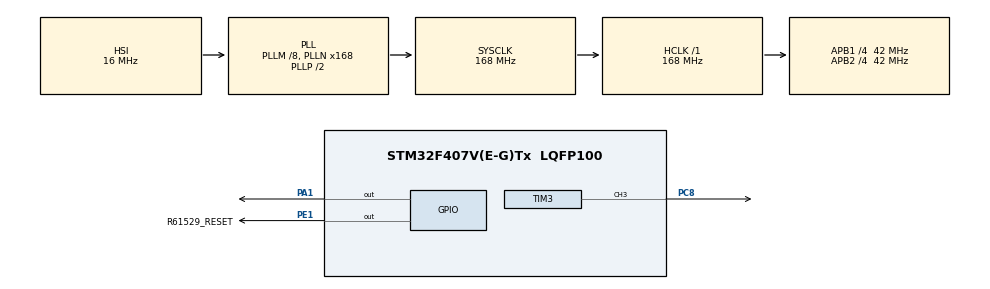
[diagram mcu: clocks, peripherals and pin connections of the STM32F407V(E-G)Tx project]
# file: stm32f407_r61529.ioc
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Mcu.Family=STM32F4
Mcu.Name=STM32F407V(E-G)Tx
Mcu.Package=LQFP100
NVIC.PriorityGroup=NVIC_PRIORITYGROUP_4
PA1.Signal=GPIO_Output
PC8.Signal=S_TIM3_CH3
PE1.GPIO_Label=R61529_RESET
PE1.Signal=GPIO_Output
ProjectManager.HeapSize=0x200
ProjectManager.StackSize=0x400
ProjectManager.TargetToolchain=STM32CubeIDE
RCC.48MHZClocksFreq_Value=84000000
RCC.AHBFreq_Value=168000000
RCC.APB1CLKDivider=RCC_HCLK_DIV4
RCC.APB1Freq_Value=42000000
RCC.APB1TimFreq_Value=84000000
RCC.APB2CLKDivider=RCC_HCLK_DIV4
RCC.APB2Freq_Value=42000000
RCC.APB2TimFreq_Value=84000000
RCC.CortexFreq_Value=168000000
RCC.HCLKFreq_Value=168000000
RCC.HSE_VALUE=25000000
RCC.HSI_VALUE=16000000
RCC.LSE_VALUE=32768
RCC.PLLM=8
RCC.PLLN=168
RCC.SYSCLKFreq_VALUE=168000000
RCC.SYSCLKSource=RCC_SYSCLKSOURCE_PLLCLK
RCC.VCOOutputFreq_Value=336000000
SH.S_TIM3_CH3.0=TIM3_CH3,PWM Generation3 CH3
TIM3.Channel-PWM\ Generation3\ CH3=TIM_CHANNEL_3
TIM3.Period=14000 - 1
TIM3.Prescaler=50
TIM3.Pulse-PWM\ Generation3\ CH3=7000 - 1
board=custom

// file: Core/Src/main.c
/* USER CODE BEGIN Header */
/**
  ******************************************************************************
  * @file           : main.c
  * @brief          : Main program body
  ******************************************************************************
  * @attention
  *
  * Copyright (c) 2023 STMicroelectronics.
  * All rights reserved.
  *
  * This software is licensed under terms that can be found in the LICENSE file
  * in the root directory of this software component.
  * If no LICENSE file comes with this software, it is provided AS-IS.
  *
  ******************************************************************************
  */
/* USER CODE END Header */
#include "main.h"

/* USER CODE BEGIN Includes */
#include "systick_timer.h"
#include "r61529.h"
#include "fonts.h"

/* USER CODE END Includes */

TIM_HandleTypeDef htim3;

void SystemClock_Config(void);
static void MX_GPIO_Init(void);
static void MX_TIM3_Init(void);
/* USER CODE BEGIN PFP */
void MCU_Init();
void Blink_LED();

/* USER CODE END PFP */

/* USER CODE BEGIN 0 */
void MCU_Init(){
	GPIO_InitTypeDef GPIO_InitStruct ={0};
	/** FMC GPIO Configuration
	PE7   ------> FMC_D4
	PE8   ------> FMC_D5
	PE9   ------> FMC_D6
	PE10   ------> FMC_D7
	PE11   ------> FMC_D8
	PE12   ------> FMC_D9
	PE13   ------> FMC_D10
	PE14   ------> FMC_D11
	PE15   ------> FMC_D12
	PD8   ------> FMC_D13
	PD9   ------> FMC_D14
	PD10   ------> FMC_D15
	PD11   ------> FMC_A16
	PD14   ------> FMC_D0
	PD15   ------> FMC_D1
	PC7   ------> FMC_NE1
	PD0   ------> FMC_D2
	PD1   ------> FMC_D3
	PD4   ------> FMC_NOE
	PD5   ------> FMC_NWE
	*/
	GPIO_InitStruct.Pin = GPIO_PIN_7|GPIO_PIN_8|GPIO_PIN_9|GPIO_PIN_10|GPIO_PIN_11
							|GPIO_PIN_12|GPIO_PIN_13|GPIO_PIN_14|GPIO_PIN_15;
	GPIO_InitStruct.Mode = GPIO_MODE_OUTPUT_PP;
	GPIO_InitStruct.Pull = GPIO_NOPULL;
	GPIO_InitStruct.Speed = GPIO_SPEED_FREQ_VERY_HIGH;
	HAL_GPIO_Init(GPIOE, &GPIO_InitStruct);

	GPIO_InitStruct.Pin = GPIO_PIN_8|GPIO_PIN_9|GPIO_PIN_10|GPIO_PIN_11|GPIO_PIN_14
							|GPIO_PIN_15|GPIO_PIN_0|GPIO_PIN_1|GPIO_PIN_4|GPIO_PIN_5;
	GPIO_InitStruct.Mode = GPIO_MODE_OUTPUT_PP;
	GPIO_InitStruct.Pull = GPIO_NOPULL;
	GPIO_InitStruct.Speed = GPIO_SPEED_FREQ_VERY_HIGH;
	HAL_GPIO_Init(GPIOD, &GPIO_InitStruct);

	GPIO_InitStruct.Pin = GPIO_PIN_7;
	GPIO_InitStruct.Mode = GPIO_MODE_OUTPUT_PP;
	GPIO_InitStruct.Pull = GPIO_NOPULL;
	GPIO_InitStruct.Speed = GPIO_SPEED_FREQ_VERY_HIGH;
	HAL_GPIO_Init(GPIOC, &GPIO_InitStruct);

	/*--------------------------------------------------------------------------*/
	/*--------------------------------------------------------------------------*/
	/*--------------------------------------------------------------------------*/
	HAL_NVIC_SetPriority(SysTick_IRQn, 0x0, 0x0);
	HAL_NVIC_EnableIRQ(SysTick_IRQn);

	HAL_TIM_PWM_Start(&htim3, TIM_CHANNEL_3);
	Init_Disp();
	ili9481_FillScreen(WHITE);
	r61529_WriteString(50, 50, "Mamka mu na toja ekran...", Font_11x18, BLACK, WHITE);
}

void Blink_LED(){
	static uint8_t state = 0;

	if(wait_ms_ch(0, 750)){
		if(state == 0){
			HAL_GPIO_WritePin(GPIOA, GPIO_PIN_1, GPIO_PIN_SET);
			state = 1;
		}else{
			HAL_GPIO_WritePin(GPIOA, GPIO_PIN_1, GPIO_PIN_RESET);
			state = 0;
		}
	}
}

/* USER CODE END 0 */

int main(void)
{

  /* MCU Configuration--------------------------------------------------------*/

  /* Reset of all peripherals, Initializes the Flash interface and the Systick. */
  HAL_Init();

  /* Configure the system clock */
  SystemClock_Config();

  /* Initialize all configured peripherals */
  MX_GPIO_Init();
  MX_TIM3_Init();
  /* USER CODE BEGIN 2 */
  MCU_Init();

  /* USER CODE END 2 */

  /* Infinite loop */
  /* USER CODE BEGIN WHILE */
  while(1){
	  Blink_LED();
    /* USER CODE END WHILE */
  }
}

void SystemClock_Config(void)
{
  RCC_OscInitTypeDef RCC_OscInitStruct = {0};
  RCC_ClkInitTypeDef RCC_ClkInitStruct = {0};

  /** Configure the main internal regulator output voltage
  */
  __HAL_RCC_PWR_CLK_ENABLE();
  __HAL_PWR_VOLTAGESCALING_CONFIG(PWR_REGULATOR_VOLTAGE_SCALE1);

  /** Initializes the RCC Oscillators according to the specified parameters
  * in the RCC_OscInitTypeDef structure.
  */
  RCC_OscInitStruct.OscillatorType = RCC_OSCILLATORTYPE_HSI;
  RCC_OscInitStruct.HSIState = RCC_HSI_ON;
  RCC_OscInitStruct.HSICalibrationValue = RCC_HSICALIBRATION_DEFAULT;
  RCC_OscInitStruct.PLL.PLLState = RCC_PLL_ON;
  RCC_OscInitStruct.PLL.PLLSource = RCC_PLLSOURCE_HSI;
  RCC_OscInitStruct.PLL.PLLM = 8;
  RCC_OscInitStruct.PLL.PLLN = 168;
  RCC_OscInitStruct.PLL.PLLP = RCC_PLLP_DIV2;
  RCC_OscInitStruct.PLL.PLLQ = 4;
  if (HAL_RCC_OscConfig(&RCC_OscInitStruct) != HAL_OK)
  {
    Error_Handler();
  }

  /** Initializes the CPU, AHB and APB buses clocks
  */
  RCC_ClkInitStruct.ClockType = RCC_CLOCKTYPE_HCLK|RCC_CLOCKTYPE_SYSCLK
                              |RCC_CLOCKTYPE_PCLK1|RCC_CLOCKTYPE_PCLK2;
  RCC_ClkInitStruct.SYSCLKSource = RCC_SYSCLKSOURCE_PLLCLK;
  RCC_ClkInitStruct.AHBCLKDivider = RCC_SYSCLK_DIV1;
  RCC_ClkInitStruct.APB1CLKDivider = RCC_HCLK_DIV4;
  RCC_ClkInitStruct.APB2CLKDivider = RCC_HCLK_DIV4;

  if (HAL_RCC_ClockConfig(&RCC_ClkInitStruct, FLASH_LATENCY_5) != HAL_OK)
  {
    Error_Handler();
  }
}

static void MX_TIM3_Init(void)
{

  TIM_MasterConfigTypeDef sMasterConfig = {0};
  TIM_OC_InitTypeDef sConfigOC = {0};

  htim3.Instance = TIM3;
  htim3.Init.Prescaler = 50;
  htim3.Init.CounterMode = TIM_COUNTERMODE_UP;
  htim3.Init.Period = 14000 - 1;
  htim3.Init.ClockDivision = TIM_CLOCKDIVISION_DIV1;
  htim3.Init.AutoReloadPreload = TIM_AUTORELOAD_PRELOAD_DISABLE;
  if (HAL_TIM_PWM_Init(&htim3) != HAL_OK)
  {
    Error_Handler();
  }
  sMasterConfig.MasterOutputTrigger = TIM_TRGO_RESET;
  sMasterConfig.MasterSlaveMode = TIM_MASTERSLAVEMODE_DISABLE;
  if (HAL_TIMEx_MasterConfigSynchronization(&htim3, &sMasterConfig) != HAL_OK)
  {
    Error_Handler();
  }
  sConfigOC.OCMode = TIM_OCMODE_PWM1;
  sConfigOC.Pulse = 7000 - 1;
  sConfigOC.OCPolarity = TIM_OCPOLARITY_HIGH;
  sConfigOC.OCFastMode = TIM_OCFAST_DISABLE;
  if (HAL_TIM_PWM_ConfigChannel(&htim3, &sConfigOC, TIM_CHANNEL_3) != HAL_OK)
  {
    Error_Handler();
  }
  HAL_TIM_MspPostInit(&htim3);

}

static void MX_GPIO_Init(void)
{
  GPIO_InitTypeDef GPIO_InitStruct = {0};

  /* GPIO Ports Clock Enable */
  __HAL_RCC_GPIOA_CLK_ENABLE();
  __HAL_RCC_GPIOC_CLK_ENABLE();
  __HAL_RCC_GPIOD_CLK_ENABLE();
  __HAL_RCC_GPIOE_CLK_ENABLE();

  /*Configure GPIO pin Output Level */
  HAL_GPIO_WritePin(GPIOA, GPIO_PIN_1, GPIO_PIN_RESET);

  /*Configure GPIO pin Output Level */
  HAL_GPIO_WritePin(R61529_RESET_GPIO_Port, R61529_RESET_Pin, GPIO_PIN_RESET);

  /*Configure GPIO pin : PA1 */
  GPIO_InitStruct.Pin = GPIO_PIN_1;
  GPIO_InitStruct.Mode = GPIO_MODE_OUTPUT_PP;
  GPIO_InitStruct.Pull = GPIO_NOPULL;
  GPIO_InitStruct.Speed = GPIO_SPEED_FREQ_LOW;
  HAL_GPIO_Init(GPIOA, &GPIO_InitStruct);

  /*Configure GPIO pin : R61529_RESET_Pin */
  GPIO_InitStruct.Pin = R61529_RESET_Pin;
  GPIO_InitStruct.Mode = GPIO_MODE_OUTPUT_PP;
  GPIO_InitStruct.Pull = GPIO_NOPULL;
  GPIO_InitStruct.Speed = GPIO_SPEED_FREQ_LOW;
  HAL_GPIO_Init(R61529_RESET_GPIO_Port, &GPIO_InitStruct);

}

void Error_Handler(void)
{
  __disable_irq();
  while (1)
  {
  }
}
